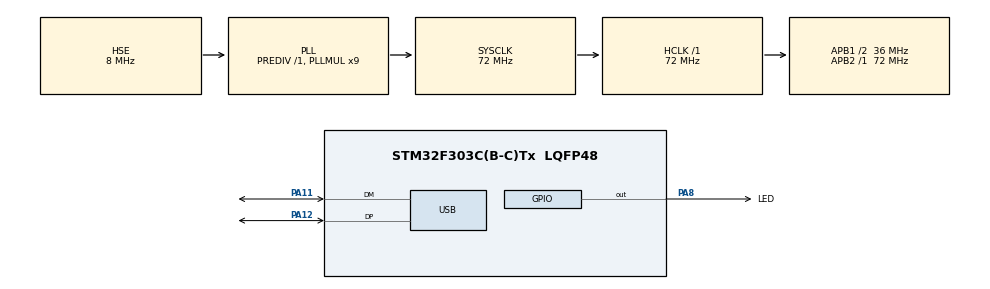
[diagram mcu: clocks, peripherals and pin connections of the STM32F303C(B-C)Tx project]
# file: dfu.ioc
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Mcu.Family=STM32F3
Mcu.Name=STM32F303C(B-C)Tx
Mcu.Package=LQFP48
NVIC.PriorityGroup=NVIC_PRIORITYGROUP_4
NVIC.USB_LP_CAN_RX0_IRQn=true\:0\:0\:false\:false\:true
PA11.Mode=Device
PA11.Signal=USB_DM
PA12.Mode=Device
PA12.Signal=USB_DP
PA8.GPIO_Label=LED
PA8.Signal=GPIO_Output
PF0-OSC_IN.Mode=HSE-External-Oscillator
PF0-OSC_IN.Signal=RCC_OSC_IN
PF1-OSC_OUT.Mode=HSE-External-Oscillator
PF1-OSC_OUT.Signal=RCC_OSC_OUT
ProjectManager.HeapSize=0x200
ProjectManager.StackSize=0x400
ProjectManager.TargetToolchain=SW4STM32
RCC.AHBFreq_Value=72000000
RCC.APB1CLKDivider=RCC_HCLK_DIV2
RCC.APB1Freq_Value=36000000
RCC.APB1TimFreq_Value=72000000
RCC.APB2Freq_Value=72000000
RCC.APB2TimFreq_Value=72000000
RCC.CortexFreq_Value=72000000
RCC.HCLKFreq_Value=72000000
RCC.HSE_VALUE=8000000
RCC.HSIState=RCC_HSI_ON
RCC.HSI_VALUE=8000000
RCC.LSE_VALUE=32768
RCC.PLLMUL=RCC_PLL_MUL9
RCC.PRESCALERUSB=RCC_USBCLKSOURCE_PLL_DIV1_5
RCC.SYSCLKFreq_VALUE=72000000
RCC.SYSCLKSourceVirtual=RCC_SYSCLKSOURCE_PLLCLK
RCC.USBFreq_Value=48000000
USB_DEVICE.USBD_HandleTypeDef=hUsbDeviceFS
USB_DEVICE.VirtualMode=Dfu
USB_DEVICE.VirtualModeFS=Dfu_FS
VP_CRC_VS_CRC.Mode=CRC_Activate
VP_RTC_VS_RTC_Activate.Mode=RTC_Enabled
VP_USB_DEVICE_VS_USB_DEVICE_DFU_FS.Mode=DFU_FS
board=dfu

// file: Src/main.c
/**
  ******************************************************************************
  * File Name          : main.c
  * Description        : Main program body
  ******************************************************************************
  *
  * Copyright (c) 2017 STMicroelectronics International N.V.
  * All rights reserved.
  *
  * Redistribution and use in source and binary forms, with or without
  * modification, are permitted, provided that the following conditions are met:
  *
  * 1. Redistribution of source code must retain the above copyright notice,
  *    this list of conditions and the following disclaimer.
  * 2. Redistributions in binary form must reproduce the above copyright notice,
  *    this list of conditions and the following disclaimer in the documentation
  *    and/or other materials provided with the distribution.
  * 3. Neither the name of STMicroelectronics nor the names of other
  *    contributors to this software may be used to endorse or promote products
  *    derived from this software without specific written permission.
  * 4. This software, including modifications and/or derivative works of this
  *    software, must execute solely and exclusively on microcontroller or
  *    microprocessor devices manufactured by or for STMicroelectronics.
  * 5. Redistribution and use of this software other than as permitted under
  *    this license is void and will automatically terminate your rights under
  *    this license.
  *
  * THIS SOFTWARE IS PROVIDED BY STMICROELECTRONICS AND CONTRIBUTORS "AS IS"
  * AND ANY EXPRESS, IMPLIED OR STATUTORY WARRANTIES, INCLUDING, BUT NOT
  * LIMITED TO, THE IMPLIED WARRANTIES OF MERCHANTABILITY, FITNESS FOR A
  * PARTICULAR PURPOSE AND NON-INFRINGEMENT OF THIRD PARTY INTELLECTUAL PROPERTY
  * RIGHTS ARE DISCLAIMED TO THE FULLEST EXTENT PERMITTED BY LAW. IN NO EVENT
  * SHALL STMICROELECTRONICS OR CONTRIBUTORS BE LIABLE FOR ANY DIRECT, INDIRECT,
  * INCIDENTAL, SPECIAL, EXEMPLARY, OR CONSEQUENTIAL DAMAGES (INCLUDING, BUT NOT
  * LIMITED TO, PROCUREMENT OF SUBSTITUTE GOODS OR SERVICES; LOSS OF USE, DATA,
  * OR PROFITS; OR BUSINESS INTERRUPTION) HOWEVER CAUSED AND ON ANY THEORY OF
  * LIABILITY, WHETHER IN CONTRACT, STRICT LIABILITY, OR TORT (INCLUDING
  * NEGLIGENCE OR OTHERWISE) ARISING IN ANY WAY OUT OF THE USE OF THIS SOFTWARE,
  * EVEN IF ADVISED OF THE POSSIBILITY OF SUCH DAMAGE.
  *
  ******************************************************************************
  */
#include "stm32f3xx_hal.h"
#include "usb_device.h"
#include "stmsp_f3hw.h"

/* USER CODE BEGIN Includes */
#include "version.h"
/* USER CODE END Includes */

CRC_HandleTypeDef hcrc;

RTC_HandleTypeDef hrtc;

/* USER CODE BEGIN PV */
/* Private variables ---------------------------------------------------------*/

/* USER CODE END PV */

void SystemClock_Config(void);
void Error_Handler(void);
static void MX_GPIO_Init(void);
static void MX_CRC_Init(void);
static void MX_RTC_Init(void);

/* USER CODE BEGIN PFP */
/* Private function prototypes -----------------------------------------------*/

/* USER CODE END PFP */

/* USER CODE BEGIN 0 */
//TODO: also defined in usbd_conf.h and usbd_dfu_if.c
#define APP_START 0x08004000
#define APP_END 0x08020000
#define APP_RANGE_VALID(a, s) (!(((a) | (s)) & 3) && (a) >= APP_START && ((a) + (s)) <= APP_END)
#define VERSION_INFO_OFFSET 0x188
const version_info_t *app_info = (void *)(APP_START + VERSION_INFO_OFFSET);

static int app_ok(void) {
  if(!APP_RANGE_VALID(APP_START, app_info->image_size)) {
    return 0;
  }
  uint32_t crc = HAL_CRC_Calculate(&hcrc, (uint32_t *)APP_START, app_info->image_size / 4);

  if(crc != 0) {
    return 0;
  }
  return 1;
}
/* USER CODE END 0 */

int main(void) {

  /* MCU Configuration----------------------------------------------------------*/

  /* Reset of all peripherals, Initializes the Flash interface and the Systick. */
  HAL_Init();

  /* Configure the system clock */
  SystemClock_Config();

  // __HAL_RCC_GPIOA_CLK_ENABLE();
  // GPIO_InitTypeDef GPIO_InitStruct;
  // GPIO_InitStruct.Pin = GPIO_PIN_11 | GPIO_PIN_12;
  // GPIO_InitStruct.Mode = GPIO_MODE_OUTPUT_PP;
  // GPIO_InitStruct.Pull = GPIO_NOPULL;
  // GPIO_InitStruct.Speed = GPIO_SPEED_FREQ_LOW;
  // HAL_GPIO_Init(GPIOA, &GPIO_InitStruct);
  // HAL_GPIO_WritePin(GPIOA, GPIO_PIN_11, GPIO_PIN_RESET);
  // HAL_GPIO_WritePin(GPIOA, GPIO_PIN_12, GPIO_PIN_RESET);
  // HAL_Delay(500);

  /* Initialize all configured peripherals */
  MX_GPIO_Init();
  MX_USB_DEVICE_Init();
  MX_CRC_Init();
  MX_RTC_Init();

#ifdef USB_DISCONNECT_PIN
  GPIO_InitTypeDef GPIO_InitStruct;
  GPIO_InitStruct.Pin   = USB_DISCONNECT_PIN;
  GPIO_InitStruct.Mode  = GPIO_MODE_OUTPUT_PP;
  GPIO_InitStruct.Pull  = GPIO_NOPULL;
  GPIO_InitStruct.Speed = GPIO_SPEED_FREQ_LOW;
  HAL_GPIO_Init(USB_DISCONNECT_PORT, &GPIO_InitStruct);
  HAL_GPIO_WritePin(USB_DISCONNECT_PORT, USB_DISCONNECT_PIN, GPIO_PIN_RESET);
#endif

#ifdef USB_CONNECT_PIN
  GPIO_InitTypeDef GPIO_InitStruct;
  GPIO_InitStruct.Pin   = USB_CONNECT_PIN;
  GPIO_InitStruct.Mode  = GPIO_MODE_OUTPUT_PP;
  GPIO_InitStruct.Pull  = GPIO_NOPULL;
  GPIO_InitStruct.Speed = GPIO_SPEED_FREQ_LOW;
  HAL_GPIO_Init(USB_CONNECT_PORT, &GPIO_InitStruct);
  HAL_GPIO_WritePin(USB_CONNECT_PORT, USB_CONNECT_PIN, GPIO_PIN_SET);
#endif

  /* USER CODE BEGIN 2 */
  if(app_ok() && RTC->BKP0R == 0x00000000) {
    // SCB->VTOR = APP_START;
    /* Jump to user application */
    void (*JumpToApplication)(void);
    uint32_t JumpAddress = *(__IO uint32_t *)(USBD_DFU_APP_DEFAULT_ADD + 4);
    JumpToApplication    = (void *)JumpAddress;

    /* Initialize user application's Stack Pointer */
    __set_MSP(*(__IO uint32_t *)USBD_DFU_APP_DEFAULT_ADD);
#ifdef USB_DISCONNECT_PIN
    HAL_GPIO_WritePin(GPIOC, GPIO_PIN_13, GPIO_PIN_SET);
    HAL_Delay(100);
#endif
    JumpToApplication();
    while(1)
      ;
  }
  RTC->BKP0R = 0x00000000;
  /* USER CODE END 2 */

  /* Infinite loop */
  while(1) {

    /* USER CODE BEGIN 3 */
    HAL_GPIO_WritePin(LED_PORT, LED_PIN, GPIO_PIN_SET);
    HAL_Delay(50);
    HAL_GPIO_WritePin(LED_PORT, LED_PIN, GPIO_PIN_RESET);
    HAL_Delay(50);
  }
  /* USER CODE END 3 */
}

/** System Clock Configuration
*/
void SystemClock_Config(void) {
  RCC_OscInitTypeDef RCC_OscInitStruct;
  RCC_ClkInitTypeDef RCC_ClkInitStruct;
  RCC_PeriphCLKInitTypeDef PeriphClkInit;

  /**Initializes the CPU, AHB and APB busses clocks
    */
  RCC_OscInitStruct.OscillatorType = RCC_OSCILLATORTYPE_LSI | RCC_OSCILLATORTYPE_HSE;
  RCC_OscInitStruct.HSEState       = RCC_HSE_ON;
  RCC_OscInitStruct.HSEPredivValue = RCC_HSE_PREDIV_DIV1;
  RCC_OscInitStruct.HSIState       = RCC_HSI_ON;
  RCC_OscInitStruct.LSIState       = RCC_LSI_ON;
  RCC_OscInitStruct.PLL.PLLState   = RCC_PLL_ON;
  RCC_OscInitStruct.PLL.PLLSource  = RCC_PLLSOURCE_HSE;
  RCC_OscInitStruct.PLL.PLLMUL     = RCC_PLL_MUL9;
  if(HAL_RCC_OscConfig(&RCC_OscInitStruct) != HAL_OK) {
    Error_Handler();
  }

  /**Initializes the CPU, AHB and APB busses clocks
    */
  RCC_ClkInitStruct.ClockType      = RCC_CLOCKTYPE_HCLK | RCC_CLOCKTYPE_SYSCLK | RCC_CLOCKTYPE_PCLK1 | RCC_CLOCKTYPE_PCLK2;
  RCC_ClkInitStruct.SYSCLKSource   = RCC_SYSCLKSOURCE_PLLCLK;
  RCC_ClkInitStruct.AHBCLKDivider  = RCC_SYSCLK_DIV1;
  RCC_ClkInitStruct.APB1CLKDivider = RCC_HCLK_DIV2;
  RCC_ClkInitStruct.APB2CLKDivider = RCC_HCLK_DIV1;

  if(HAL_RCC_ClockConfig(&RCC_ClkInitStruct, FLASH_LATENCY_2) != HAL_OK) {
    Error_Handler();
  }

  PeriphClkInit.PeriphClockSelection = RCC_PERIPHCLK_USB | RCC_PERIPHCLK_RTC;
  PeriphClkInit.RTCClockSelection    = RCC_RTCCLKSOURCE_LSI;
  PeriphClkInit.USBClockSelection    = RCC_USBCLKSOURCE_PLL_DIV1_5;
  if(HAL_RCCEx_PeriphCLKConfig(&PeriphClkInit) != HAL_OK) {
    Error_Handler();
  }

  /**Configure the Systick interrupt time
    */
  HAL_SYSTICK_Config(HAL_RCC_GetHCLKFreq() / 1000);

  /**Configure the Systick
    */
  HAL_SYSTICK_CLKSourceConfig(SYSTICK_CLKSOURCE_HCLK);

  /* SysTick_IRQn interrupt configuration */
  HAL_NVIC_SetPriority(SysTick_IRQn, 0, 0);
}

/* CRC init function */
static void MX_CRC_Init(void) {
  hcrc.Instance                     = CRC;
  hcrc.Init.DefaultPolynomialUse    = DEFAULT_POLYNOMIAL_ENABLE;
  hcrc.Init.DefaultInitValueUse     = DEFAULT_INIT_VALUE_ENABLE;
  hcrc.Init.InputDataInversionMode  = CRC_INPUTDATA_INVERSION_NONE;
  hcrc.Init.OutputDataInversionMode = CRC_OUTPUTDATA_INVERSION_DISABLE;
  hcrc.InputDataFormat              = CRC_INPUTDATA_FORMAT_WORDS;
  if(HAL_CRC_Init(&hcrc) != HAL_OK) {
    Error_Handler();
  }
}

/* RTC init function */
static void MX_RTC_Init(void) {
  /**Initialize RTC Only
    */
  hrtc.Instance            = RTC;
  hrtc.Init.HourFormat     = RTC_HOURFORMAT_24;
  hrtc.Init.AsynchPrediv   = 127;
  hrtc.Init.SynchPrediv    = 255;
  hrtc.Init.OutPut         = RTC_OUTPUT_DISABLE;
  hrtc.Init.OutPutPolarity = RTC_OUTPUT_POLARITY_HIGH;
  hrtc.Init.OutPutType     = RTC_OUTPUT_TYPE_OPENDRAIN;
  if(HAL_RTC_Init(&hrtc) != HAL_OK) {
    Error_Handler();
  }
}

/** Configure pins as
        * Analog
        * Input
        * Output
        * EVENT_OUT
        * EXTI
*/
static void MX_GPIO_Init(void) {
  GPIO_InitTypeDef GPIO_InitStruct;

  /* GPIO Ports Clock Enable */
  __HAL_RCC_GPIOF_CLK_ENABLE();
  __HAL_RCC_GPIOA_CLK_ENABLE();

  /*Configure GPIO pin Output Level */
  HAL_GPIO_WritePin(LED_PORT, LED_PIN, GPIO_PIN_RESET);

  /*Configure GPIO pin : LED_PIN */
  GPIO_InitStruct.Pin   = LED_PIN;
  GPIO_InitStruct.Mode  = GPIO_MODE_OUTPUT_PP;
  GPIO_InitStruct.Pull  = GPIO_NOPULL;
  GPIO_InitStruct.Speed = GPIO_SPEED_FREQ_LOW;
  HAL_GPIO_Init(LED_PORT, &GPIO_InitStruct);
}

void Error_Handler(void) {
  while(1) {
  }
}

/************************ (C) COPYRIGHT STMicroelectronics *****END OF FILE****/
